# AT90PWM3B register map
Vendor: Atmel; File version: 1.0
CPU: other r0p0, little endian, no MPU, no FPU, 4 interrupt priority bits
Registers are 8-bit, read-write, reset 0x0 unless marked. A register's access mark holds for its fields unless they carry their own. Offsets are from the block's base; [hi:lo] are bit positions.

## FUSE — Fuses
Base 0x00800000
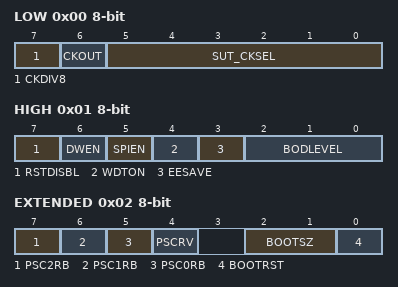
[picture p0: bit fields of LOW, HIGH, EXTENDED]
0x00 LOW
  [7] CKDIV8 — Divide clock by 8 internally
  [6] CKOUT — Clock output on PORTB0
  [5:0] SUT_CKSEL — Select Clock Source
    0=EXTCLK_6CK_14CK_0MS (Ext. Clock; Start-up time PWRDWN/RESET: 6 CK/14 CK + 0 ms); 1=PLLCLK_PLLIN_EXTCLK_6KCK_14CK_0MS (PLL clock /4; PLL input: Ext. Clock; Start-up time PWRDWN/RESET: 6K CK/14 CK + 0 ms); 2=INTRCOSC_8MHZ_6CK_14CK_0MS (Int. RC Osc. 8 MHz; Start-up time PWRDWN/RESET: 6 CK/14 CK + 0 ms); 3=PLLCLK_16MHZ_1KCK_14CK_0MS (PLL clock 16 MHz; Rc. Start-up time PWRDWN/RESET: 1K CK/14 CK + 0 ms); 4=EXTXOSC_PLLIN_EXTXOSC_1KCK_14CK_0MS (Ext. Crystal Osc.; PLL input: Ext. Crystal Osc.; Start-up time PWRDWN/RESET: 1K CK/14 CK + 0 ms); 5=PLLCLK_PLLIN_EXTXOSC_1KCK_14CK_0MS (PLL clock /4; PLL input: Ext. Crystal Osc.; Start-up time PWRDWN/RESET: 1K CK/14 CK + 0 ms); 8=EXTXOSC_0MHZ4_0MHZ9_258CK_14CK_4MS1 (Ext. Crystal Osc. 0.4-0.9 MHz; Start-up time PWRDWN/RESET: 258 CK/14 CK + 4.1 ms); 9=EXTXOSC_0MHZ4_0MHZ9_1KCK_14CK_65MS (Ext. Crystal Osc. 0.4-0.9 MHz; Start-up time PWRDWN/RESET: 1K CK /14 CK + 65 ms); 10=EXTXOSC_0MHZ9_3MHZ_258CK_14CK_4MS1 (Ext. Crystal Osc. 0.9-3.0 MHz; Start-up time PWRDWN/RESET: 258 CK/14 CK + 4.1 ms); 11=EXTXOSC_0MHZ9_3MHZ_1KCK_14CK_65MS (Ext. Crystal Osc. 0.9-3.0 MHz; Start-up time PWRDWN/RESET: 1K CK /14 CK + 65 ms); 12=EXTXOSC_3MHZ_8MHZ_258CK_14CK_4MS1 (Ext. Crystal Osc. 3.0-8.0 MHz; Start-up time PWRDWN/RESET: 258 CK/14 CK + 4.1 ms); 13=EXTXOSC_3MHZ_8MHZ_1KCK_14CK_65MS (Ext. Crystal Osc. 3.0-8.0 MHz; Start-up time PWRDWN/RESET: 1K CK /14 CK + 65 ms); 14=EXTXOSC_8MHZ_XX_258CK_14CK_4MS1 (Ext. Crystal Osc. 8.0- MHz; Start-up time PWRDWN/RESET: 258 CK/14 CK + 4.1 ms); 15=EXTXOSC_8MHZ_XX_1KCK_14CK_65MS (Ext. Crystal Osc. 8.0- MHz; Start-up time PWRDWN/RESET: 1K CK /14 CK + 65 ms); 16=EXTCLK_6CK_14CK_4MS1 (Ext. Clock; Start-up time PWRDWN/RESET: 6 CK/14 CK + 4.1 ms); 17=PLLCLK_PLLIN_EXTCLK_6KCK_14CK_4MS (PLL clock /4; PLL input: Ext. Clock; Start-up time PWRDWN/RESET: 6K CK/14 CK + 4 ms); 18=INTRCOSC_8MHZ_6CK_14CK_4MS1 (Int. RC Osc. 8 MHz; Start-up time PWRDWN/RESET: 6 CK/14 CK + 4.1 ms); 19=PLLCLK_16MHZ_1KCK_14CK_4MS1 (PLL clock 16 MHz; Start-up time PWRDWN/RESET: 1K CK/14 CK + 4.1 ms); 20=EXTXOSC_PLLIN_EXTXOSC_1KCK_14CK_4MS (Ext. Crystal Osc.; PLL input: Ext. Crystal Osc.; Start-up time PWRDWN/RESET: 1K CK/14 CK + 4 ms); 21=PLLCLK_PLLIN_EXTXOSC_1KCK_14CK_4MS (PLL clock /4; PLL input: Ext. Crystal Osc.; Start-up time PWRDWN/RESET: 1K CK/14 CK + 4 ms); 24=EXTXOSC_0MHZ4_0MHZ9_258CK_14CK_65MS (Ext. Crystal Osc. 0.4-0.9 MHz; Start-up time PWRDWN/RESET: 258 CK/14 CK + 65 ms); 25=EXTXOSC_0MHZ4_0MHZ9_16KCK_14CK_0MS (Ext. Crystal Osc. 0.4-0.9 MHz; Start-up time PWRDWN/RESET: 16K CK/14 CK + 0 ms); 26=EXTXOSC_0MHZ9_3MHZ_258CK_14CK_65MS (Ext. Crystal Osc. 0.9-3.0 MHz; Start-up time PWRDWN/RESET: 258 CK/14 CK + 65 ms); 27=EXTXOSC_0MHZ9_3MHZ_16KCK_14CK_0MS (Ext. Crystal Osc. 0.9-3.0 MHz; Start-up time PWRDWN/RESET: 16K CK/14 CK + 0 ms); 28=EXTXOSC_3MHZ_8MHZ_258CK_14CK_65MS (Ext. Crystal Osc. 3.0-8.0 MHz; Start-up time PWRDWN/RESET: 258 CK/14 CK + 65 ms); 29=EXTXOSC_3MHZ_8MHZ_16KCK_14CK_0MS (Ext. Crystal Osc. 3.0-8.0 MHz; Start-up time PWRDWN/RESET: 16K CK/14 CK + 0 ms); 30=EXTXOSC_8MHZ_XX_258CK_14CK_65MS (Ext. Crystal Osc. 8.0- MHz; Start-up time PWRDWN/RESET: 258 CK/14 CK + 65 ms); 31=EXTXOSC_8MHZ_XX_16KCK_14CK_0MS (Ext. Crystal Osc. 8.0- MHz; Start-up time PWRDWN/RESET: 16K CK/14 CK + 0 ms); 32=EXTCLK_6CK_14CK_65MS (Ext. Clock; Start-up time PWRDWN/RESET: 6 CK/14 CK + 65 ms); 33=PLLCLK_PLLIN_EXTCLK_6KCK_14CK_64MS (PLL clock /4; PLL input: Ext. Clock; Start-up time PWRDWN/RESET: 6K CK/14 CK + 64 ms); 34=INTRCOSC_8MHZ_6CK_14CK_65MS (Int. RC Osc. 8 MHz; Start-up time PWRDWN/RESET: 6 CK/14 CK + 65 ms); 35=PLLCLK_16MHZ_1KCK_14CK_65MS (PLL clock 16 MHz; Start-up time PWRDWN/RESET: 1K CK/14 CK + 65 ms); 36=EXTXOSC_PLLIN_EXTXOSC_16KCK_14CK_4MS (Ext. Crystal Osc.; PLL input: Ext. Crystal Osc.; Start-up time PWRDWN/RESET: 16K CK/14 CK + 4 ms); 37=PLLCLK_PLLIN_EXTXOSC_16KCK_14CK_4MS (PLL clock /4; PLL input: Ext. Crystal Osc.; Start-up time PWRDWN/RESET: 16K CK/14 CK + 4 ms); 40=EXTXOSC_0MHZ4_0MHZ9_1KCK_14CK_0MS (Ext. Crystal Osc. 0.4-0.9 MHz; Start-up time PWRDWN/RESET: 1K CK /14 CK + 0 ms); 41=EXTXOSC_0MHZ4_0MHZ9_16KCK_14CK_4MS1 (Ext. Crystal Osc. 0.4-0.9 MHz; Start-up time PWRDWN/RESET: 16K CK/14 CK + 4.1 ms); 42=EXTXOSC_0MHZ9_3MHZ_1KCK_14CK_0MS (Ext. Crystal Osc. 0.9-3.0 MHz; Start-up time PWRDWN/RESET: 1K CK /14 CK + 0 ms); 43=EXTXOSC_0MHZ9_3MHZ_16KCK_14CK_4MS1 (Ext. Crystal Osc. 0.9-3.0 MHz; Start-up time PWRDWN/RESET: 16K CK/14 CK + 4.1 ms); 44=EXTXOSC_3MHZ_8MHZ_1KCK_14CK_0MS (Ext. Crystal Osc. 3.0-8.0 MHz; Start-up time PWRDWN/RESET: 1K CK /14 CK + 0 ms); 45=EXTXOSC_3MHZ_8MHZ_16KCK_14CK_4MS1 (Ext. Crystal Osc. 3.0-8.0 MHz; Start-up time PWRDWN/RESET: 16K CK/14 CK + 4.1 ms); 46=EXTXOSC_8MHZ_XX_1KCK_14CK_0MS (Ext. Crystal Osc. 8.0- MHz; Start-up time PWRDWN/RESET: 1K CK /14 CK + 0 ms); 47=EXTXOSC_8MHZ_XX_16KCK_14CK_4MS1 (Ext. Crystal Osc. 8.0- MHz; Start-up time PWRDWN/RESET: 16K CK/14 CK + 4.1 ms); 51=PLLCLK_16MHZ_16KCK_14CK_0MS (PLL clock 16 MHz; Start-up time PWRDWN/RESET: 16K CK/14 CK + 0 ms); 52=EXTXOSC_PLLIN_EXTXOSC_16KCK_14CK_64MS (Ext. Crystal Osc.; PLL input: Ext. Crystal Osc.; Start-up time PWRDWN/RESET: 16K CK/14 CK + 64 ms); 53=PLLCLK_PLLIN_EXTXOSC_16KCK_14CK_64MS (PLL clock /4; PLL input: Ext. Crystal Osc.; Start-up time PWRDWN/RESET: 16K CK/14 CK + 64 ms); 56=EXTXOSC_0MHZ4_0MHZ9_1KCK_14CK_4MS1 (Ext. Crystal Osc. 0.4-0.9 MHz; Start-up time PWRDWN/RESET: 1K CK /14 CK + 4.1 ms); 57=EXTXOSC_0MHZ4_0MHZ9_16KCK_14CK_65MS (Ext. Crystal Osc. 0.4-0.9 MHz; Start-up time PWRDWN/RESET: 16K CK/14 CK + 65 ms); 58=EXTXOSC_0MHZ9_3MHZ_1KCK_14CK_4MS1 (Ext. Crystal Osc. 0.9-3.0 MHz; Start-up time PWRDWN/RESET: 1K CK /14 CK + 4.1 ms); 59=EXTXOSC_0MHZ9_3MHZ_16KCK_14CK_65MS (Ext. Crystal Osc. 0.9-3.0 MHz; Start-up time PWRDWN/RESET: 16K CK/14 CK + 65 ms); 60=EXTXOSC_3MHZ_8MHZ_1KCK_14CK_4MS1 (Ext. Crystal Osc. 3.0-8.0 MHz; Start-up time PWRDWN/RESET: 1K CK /14 CK + 4.1 ms); 61=EXTXOSC_3MHZ_8MHZ_16KCK_14CK_65MS (Ext. Crystal Osc. 3.0-8.0 MHz; Start-up time PWRDWN/RESET: 16K CK/14 CK + 65 ms); 62=EXTXOSC_8MHZ_XX_1KCK_14CK_4MS1 (Ext. Crystal Osc. 8.0- MHz; Start-up time PWRDWN/RESET: 1K CK /14 CK + 4.1 ms); 63=EXTXOSC_8MHZ_XX_16KCK_14CK_65MS (Ext. Crystal Osc. 8.0- MHz; Start-up time PWRDWN/RESET: 16K CK/14 CK + 65 ms)
0x01 HIGH
  [7] RSTDISBL — Reset Disabled (Enable PC6 as i/o pin)
  [6] DWEN — Debug Wire enable
  [5] SPIEN — Serial program downloading (SPI) enabled
  [4] WDTON — Watch-dog Timer always on
  [3] EESAVE — Preserve EEPROM through the Chip Erase cycle
  [2:0] BODLEVEL — Brown-out Detector Trigger Level
    0=2V6 (Brown-out detection at VCC=2.6 V); 1=2V8 (Brown-out detection at VCC=2.8 V); 2=4V2 (Brown-out detection at VCC=4.2 V); 3=4V4 (Brown-out detection at VCC=4.4 V); 4=4V3 (Brown-out detection at VCC=4.3 V); 5=2V7 (Brown-out detection at VCC=2.7 V); 6=4V5 (Brown-out detection at VCC=4.5 V); 7=DISABLED (Brown-out detection disabled)
0x02 EXTENDED
  [7] PSC2RB — PSC2 Reset Behavior
  [6] PSC1RB — PSC1 Reset Behavior
  [5] PSC0RB — PSC0 Reset Behavior
  [4] PSCRV — PSCOUT Reset Value
  [2:1] BOOTSZ — Select Boot Size
    0=1024W_0C00 (Boot Flash size=1024 words Boot address=$0C00); 1=512W_0E00 (Boot Flash size=512 words Boot address=$0E00); 2=256W_0F00 (Boot Flash size=256 words Boot address=$0F00); 3=128W_0F80 (Boot Flash size=128 words Boot address=$0F80)
  [0] BOOTRST — Select Reset Vector
